# ATSAMG55J19 register map
Vendor: Microchip Technology; Series: SAMG55; File version: 0
CPU: CM4 r0p1, little endian, MPU, FPU, 4 interrupt priority bits, 50 interrupts
Registers are 32-bit, read-write, reset 0x0 unless marked. A register's access mark holds for its fields unless they carry their own. Offsets are from the block's base; [hi:lo] are bit positions.

## CRCCU — Cyclic Redundancy Check Calculation Unit
Base 0x40048000
0x00 DSCR — CRCCU Descriptor Base Register
  [31:9] DSCR — Descriptor Base Address
0x08 DMA_EN wo — CRCCU DMA Enable Register
  [0] DMAEN — DMA Enable
0x0C DMA_DIS wo — CRCCU DMA Disable Register
  [0] DMADIS — DMA Disable
0x10 DMA_SR ro — CRCCU DMA Status Register
  [0] DMASR — DMA Status
0x14 DMA_IER wo — CRCCU DMA Interrupt Enable Register
  [0] DMAIER — Interrupt Enable
0x18 DMA_IDR wo — CRCCU DMA Interrupt Disable Register
  [0] DMAIDR — Interrupt Disable
0x1C DMA_IMR ro — CRCCU DMA Interrupt Mask Register
  [0] DMAIMR — Interrupt Mask
0x20 DMA_ISR ro — CRCCU DMA Interrupt Status Register
  [0] DMAISR — Interrupt Status
0x34 CR wo — CRCCU Control Register
  [0] RESET — CRC Computation Reset
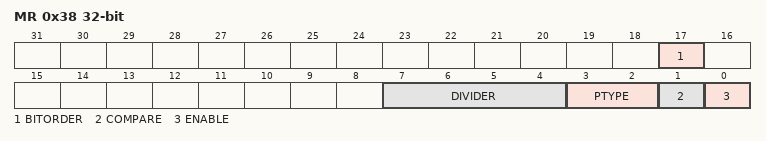
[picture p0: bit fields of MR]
0x38 MR — CRCCU Mode Register
  [17] BITORDER — Precomputation Bit Swap Operation of the CRC
    0=MSBFIRST (CRC computation is performed from the most significant bit to the least significant bit); 1=LSBFIRST (CRC computation is performed from the least significant bit to the most significant bit)
  [7:4] DIVIDER — Request Divider
  [3:2] PTYPE — Primitive Polynomial
    0=CCITT8023 (Polynom 0x04C11DB7); 1=CASTAGNOLI (Polynom 0x1EDC6F41); 2=CCITT16 (Polynom 0x1021)
  [1] COMPARE — CRC Compare
  [0] ENABLE — CRC Enable
0x3C SR ro — CRCCU Status Register
  [31:0] CRC — Cyclic Redundancy Check Value
0x40 IER wo — CRCCU Interrupt Enable Register
  [0] ERRIER — CRC Error Interrupt Enable
0x44 IDR wo — CRCCU Interrupt Disable Register
  [0] ERRIDR — CRC Error Interrupt Disable
0x48 IMR ro — CRCCU Interrupt Mask Register
  [0] ERRIMR — CRC Error Interrupt Mask
0x4C ISR ro — CRCCU Interrupt Status Register
  [0] ERRISR — CRC Error Interrupt Status

## EFC — Embedded Flash Controller
Base 0x400E0A00
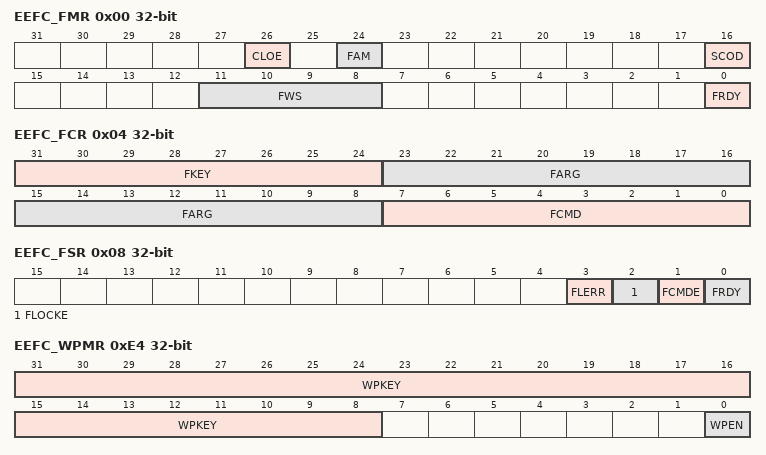
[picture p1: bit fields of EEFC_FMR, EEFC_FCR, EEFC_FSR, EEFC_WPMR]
0x00 EEFC_FMR — EEFC Flash Mode Register
  [26] CLOE — Code Loop Optimization Enable
  [24] FAM — Flash Access Mode
  [16] SCOD — Sequential Code Optimization Disable
  [11:8] FWS — Flash Wait State
  [0] FRDY — Flash Ready Interrupt Enable
0x04 EEFC_FCR wo — EEFC Flash Command Register
  [31:24] FKEY — Flash Writing Protection Key
    90=PASSWD (The 0x5A value enables the command defined by the bits of the register. If the field is written with a different value, the write is not performed and no action is started.)
  [23:8] FARG — Flash Command Argument
  [7:0] FCMD — Flash Command
    0=GETD (Get Flash descriptor); 1=WP (Write page); 2=WPL (Write page and lock); 3=EWP (Erase page and write page); 4=EWPL (Erase page and write page then lock); 5=EA (Erase all); 7=EPA (Erase pages); 8=SLB (Set lock bit); 9=CLB (Clear lock bit); 10=GLB (Get lock bit); 11=SGPB (Set GPNVM bit); 12=CGPB (Clear GPNVM bit); 13=GGPB (Get GPNVM bit); 14=STUI (Start read unique identifier); 15=SPUI (Stop read unique identifier); 16=GCALB (Get CALIB bit); 17=ES (Erase sector); 18=WUS (Write user signature); 19=EUS (Erase user signature); 20=STUS (Start read user signature); 21=SPUS (Stop read user signature)
0x08 EEFC_FSR ro — EEFC Flash Status Register
  [3] FLERR — Flash Error Status (cleared when a programming operation starts)
  [2] FLOCKE — Flash Lock Error Status (cleared on read)
  [1] FCMDE — Flash Command Error Status (cleared on read or by writing EEFC_FCR)
  [0] FRDY — Flash Ready Status (cleared when Flash is busy)
0x0C EEFC_FRR ro — EEFC Flash Result Register
  [31:0] FVALUE — Flash Result Value
0xE4 EEFC_WPMR — Write Protection Mode Register
  [31:8] WPKEY — Write Protection Key
    0x454643=PASSWD (Writing any other value in this field aborts the write operation.Always reads as 0.)
  [0] WPEN — Write Protection Enable
